# DPHY_RX0_MMR_SLV_K3_DPHY_WRAP register map
Vendor: Texas Instruments
Peripheral module from a debugger description file (folder J7ES).
Registers are 32-bit, access per field, reset 0x0 unless marked. A register's access mark holds for its fields unless they carry their own. Offsets are as the file gives them; lines under a group give offsets from that group; [hi:lo] are bit positions; {n}, {i} and the like mark numbered series; 'fields as' and 'values as' point back to an identical list; <NAME> marks a mode.

## DPHY_RX0_MMR_SLV_K3_DPHY_WRAP
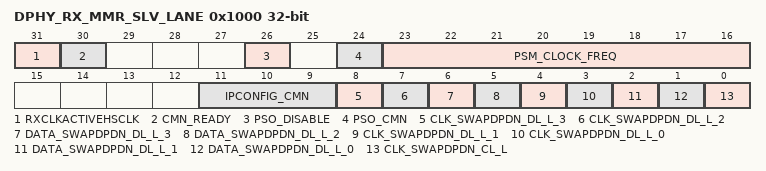
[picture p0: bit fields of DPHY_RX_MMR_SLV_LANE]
0x1000 DPHY_RX_MMR_SLV_LANE — control and status
  [31] RXCLKACTIVEHSCLK ro — Receiver high speed clock active: Driven active when the receiver high speed clock is active.
  [30] CMN_READY ro — Common ready indication: Indicates the completion of the startup process of the common module.
  [26] PSO_DISABLE rw — Disable power shut off: Disables the ability to switch off the analog switched power islands in the
  [24] PSO_CMN rw — Disable power shut off: Power Shutoff signal for CMN
  [23:16] PSM_CLOCK_FREQ rw — PMA state machine clock frequency divider control: This signal specifies a divider value used to create an internal divided clock that is a function of the psm_clock clock.
  [11:9] IPCONFIG_CMN rw — This signal decides which clock
  [8] CLK_SWAPDPDN_DL_L_3 rw — Swap DP and DN: When enabled, the rx_p and rx_m differential pins will be swapped.
  [7] CLK_SWAPDPDN_DL_L_2 rw — Swap DP and DN: When enabled, the rx_p and rx_m differential pins will be swapped.
  [6] DATA_SWAPDPDN_DL_L_3 rw — Swap DP and DN: When enabled, the rx_p and rx_m differential pins will be swapped.
  [5] DATA_SWAPDPDN_DL_L_2 rw — Swap DP and DN: When enabled, the rx_p and rx_m differential pins will be swapped.
  [4] CLK_SWAPDPDN_DL_L_1 rw — Swap DP and DN: When enabled, the rx_p and rx_m differential pins will be swapped.
  [3] CLK_SWAPDPDN_DL_L_0 rw — Swap DP and DN: When enabled, the rx_p and rx_m differential pins will be swapped.
  [2] DATA_SWAPDPDN_DL_L_1 rw — Swap DP and DN: When enabled, the rx_p and rx_m differential pins will be swapped.
  [1] DATA_SWAPDPDN_DL_L_0 rw — Swap DP and DN: When enabled, the rx_p and rx_m differential pins will be swapped.
  [0] CLK_SWAPDPDN_CL_L rw — Swap DP and DN: When enabled, the rx_p and rx_m differential pins will be swapped.
